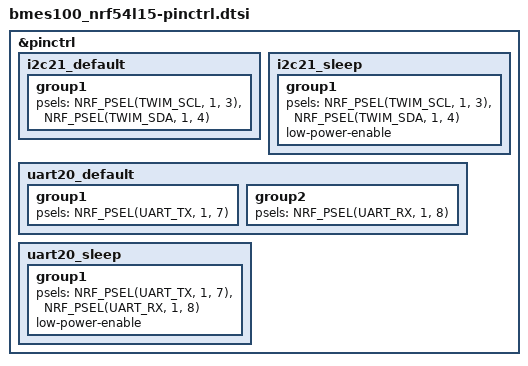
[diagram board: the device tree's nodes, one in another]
/*
 * Copyright (c) 2024 Nordic Semiconductor ASA
 * SPDX-License-Identifier: Apache-2.0
 */

&pinctrl {

	/omit-if-no-ref/ i2c21_default: i2c21_default {
		group1 {
			psels = <NRF_PSEL(TWIM_SCL, 1, 3)>,
				<NRF_PSEL(TWIM_SDA, 1, 4)>;
		};
	};

	/omit-if-no-ref/ i2c21_sleep: i2c21_sleep {
		group1 {
			psels = <NRF_PSEL(TWIM_SCL, 1, 3)>,
				<NRF_PSEL(TWIM_SDA, 1, 4)>;
			low-power-enable;
		};
	};

	/omit-if-no-ref/ uart20_default: uart20_default {
		group1 {
			psels = <NRF_PSEL(UART_TX, 1, 7)>;
		};

		group2 {
			psels = <NRF_PSEL(UART_RX, 1, 8)>;
			// bias-pull-up;
		};
	};

	/omit-if-no-ref/ uart20_sleep: uart20_sleep {
		group1 {
			psels = <NRF_PSEL(UART_TX, 1, 7)>,
				<NRF_PSEL(UART_RX, 1, 8)>;
			low-power-enable;
		};
	};
};
